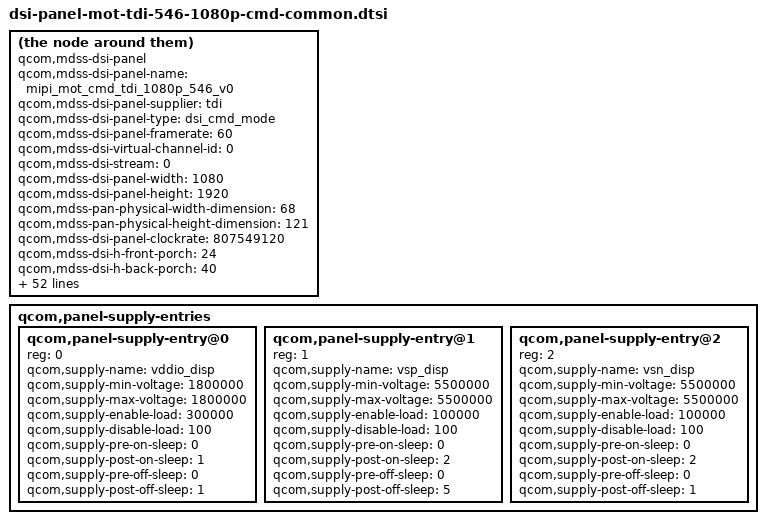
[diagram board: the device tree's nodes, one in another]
/* Copyright (c) 2015, The Linux Foundation. All rights reserved.
 *
 * This program is free software; you can redistribute it and/or modify
 * it under the terms of the GNU General Public License version 2 and
 * only version 2 as published by the Free Software Foundation.
 *
 * This program is distributed in the hope that it will be useful,
 * but WITHOUT ANY WARRANTY; without even the implied warranty of
 * MERCHANTABILITY or FITNESS FOR A PARTICULAR PURPOSE.  See the
 * GNU General Public License for more details.
 */

compatible = "qcom,mdss-dsi-panel";
qcom,mdss-dsi-panel-name = "mipi_mot_cmd_tdi_1080p_546_v0";
qcom,mdss-dsi-panel-supplier = "tdi";
qcom,mdss-dsi-panel-type = "dsi_cmd_mode";
qcom,mdss-dsi-panel-framerate = <60>;
qcom,mdss-dsi-virtual-channel-id = <0>;
qcom,mdss-dsi-stream = <0>;
qcom,mdss-dsi-panel-width = <1080>;
qcom,mdss-dsi-panel-height = <1920>;
qcom,mdss-pan-physical-width-dimension = <68>;
qcom,mdss-pan-physical-height-dimension = <121>;

qcom,mdss-dsi-panel-clockrate = <807549120>;
qcom,mdss-dsi-h-front-porch = <24>;
qcom,mdss-dsi-h-back-porch = <40>;
qcom,mdss-dsi-h-pulse-width = <4>;
qcom,mdss-dsi-h-sync-skew = <0>;
qcom,mdss-dsi-v-back-porch = <16>;
qcom,mdss-dsi-v-front-porch = <16>;
qcom,mdss-dsi-v-pulse-width = <2>;
qcom,mdss-dsi-h-left-border = <0>;
qcom,mdss-dsi-h-right-border = <0>;
qcom,mdss-dsi-v-top-border = <0>;
qcom,mdss-dsi-v-bottom-border = <0>;
qcom,mdss-dsi-bpp = <24>;
qcom,mdss-dsi-underflow-color = <0xff>;
qcom,mdss-dsi-border-color = <0>;
qcom,mdss-dsi-on-command = [
	15 01 00 00 00 00 02 FF 26 /* Touch improvements start */
	15 01 00 00 00 00 02 31 30
	15 01 00 00 00 00 02 52 30
	15 01 00 00 00 00 02 6c 30
	15 01 00 00 00 00 02 82 30
	15 01 00 00 00 00 02 FB 01
	15 01 00 00 00 00 02 FF 10 /* Touch improvements end */
	15 01 00 00 00 00 02 FF 23 /* CABC config start */
	15 01 00 00 00 00 02 13 FF
	15 01 00 00 00 00 02 14 F5
	15 01 00 00 00 00 02 15 ED
	15 01 00 00 00 00 02 16 E5
	15 01 00 00 00 00 02 FB 01
	15 01 00 00 00 00 02 39 95
	15 01 00 00 00 00 02 07 00
	15 01 00 00 00 00 02 08 02
	15 01 00 00 00 00 02 46 B8
	15 01 00 00 00 00 02 FF 10 /* CABC config end */
	05 01 00 00 64 00 01 11
	39 01 00 00 00 00 03 44 07 08
	15 01 00 00 00 00 02 35 00
	15 01 00 00 00 00 02 51 CC
	15 01 00 00 00 00 02 53 2C
	15 01 00 00 00 00 02 55 01
	05 01 00 00 00 00 01 29];	/* display on */
qcom,mdss-dsi-off-command = [
	05 01 00 00 0a 00 01 28		/* display_off */
	05 01 00 00 78 00 01 10];	/* enter sleep mode */

qcom,mdss-dsi-on-command-state = "dsi_lp_mode";
qcom,mdss-dsi-off-command-state = "dsi_lp_mode";
qcom,mdss-dsi-bllp-eof-power-mode; //todo: Check if this can be removed
qcom,mdss-dsi-lane-0-state;
qcom,mdss-dsi-lane-1-state;
qcom,mdss-dsi-lane-2-state;
qcom,mdss-dsi-lane-3-state;
qcom,mdss-dsi-panel-timings = [d6 32 22 00 60 66 26 36 28 03 04 00];
qcom,mdss-dsi-t-clk-post = <0x1b>;
qcom,mdss-dsi-t-clk-pre = <0x28>;
qcom,mdss-dsi-bl-min-level = <1>;
qcom,mdss-dsi-bl-max-level = <255>;
qcom,mdss-dsi-bl-on-defer-delay = <40>;
qcom,mdss-dsi-dma-trigger = "trigger_sw";
qcom,mdss-dsi-mdp-trigger = "none";
qcom,mdss-dsi-bl-pmic-control-type = "bl_ctrl_wled";
qcom,mdss-dsi-reset-sequence = <0 11>, <1 11>, <0 1>, <1 11>;
qcom,mdss-dsi-lp11-init;
qcom,mdss-dsi-tx-eot-append;

qcom,mdss-dsi-te-pin-select = <1>;
qcom,mdss-dsi-te-dcs-command = <1>;
qcom,mdss-dsi-te-check-enable;
qcom,mdss-dsi-te-using-te-pin;

qcom,esd-check-enabled;
qcom,mdss-dsi-panel-status-check-mode = "reg_read";
qcom,mdss-dsi-panel-status-command = [06 01 00 01 00 00 01 0A];
qcom,mdss-dsi-panel-status-command-state = "dsi_hs_mode";
qcom,mdss-dsi-panel-status-value = <0x9c>;

qcom,mdss-dsi-panel-timings-8996 = [
	23 1e 07 08 05 03 04 a0
	23 1e 07 08 05 03 04 a0
	23 1e 07 08 05 03 04 a0
	23 1e 07 08 05 03 04 a0
	23 18 07 08 05 03 04 a0
];

qcom,panel-supply-entries {
	#address-cells = <1>;
	#size-cells = <0>;

	qcom,panel-supply-entry@0 {
		reg = <0>;
		qcom,supply-name = "vddio_disp";
		qcom,supply-min-voltage = <1800000>;
		qcom,supply-max-voltage = <1800000>;
		qcom,supply-enable-load = <300000>;
		qcom,supply-disable-load = <100>;
		qcom,supply-pre-on-sleep = <0>;
		qcom,supply-post-on-sleep = <1>;
		qcom,supply-pre-off-sleep = <0>;
		qcom,supply-post-off-sleep = <1>;
	};

	qcom,panel-supply-entry@1 {
		reg = <1>;
		qcom,supply-name = "vsp_disp";
		qcom,supply-min-voltage = <5500000>;
		qcom,supply-max-voltage = <5500000>;
		qcom,supply-enable-load = <100000>;
		qcom,supply-disable-load = <100>;
		qcom,supply-pre-on-sleep = <0>;
		qcom,supply-post-on-sleep = <2>;
		qcom,supply-pre-off-sleep = <0>;
		qcom,supply-post-off-sleep = <5>;
	};

	qcom,panel-supply-entry@2 {
		reg = <2>;
		qcom,supply-name = "vsn_disp";
		qcom,supply-min-voltage = <5500000>;
		qcom,supply-max-voltage = <5500000>;
		qcom,supply-enable-load = <100000>;
		qcom,supply-disable-load = <100>;
		qcom,supply-pre-on-sleep = <0>;
		qcom,supply-post-on-sleep = <2>;
		qcom,supply-pre-off-sleep = <0>;
		qcom,supply-post-off-sleep = <1>;
	};
};
